VERSION ""

NS_ :

BS_:

BU_: XXX

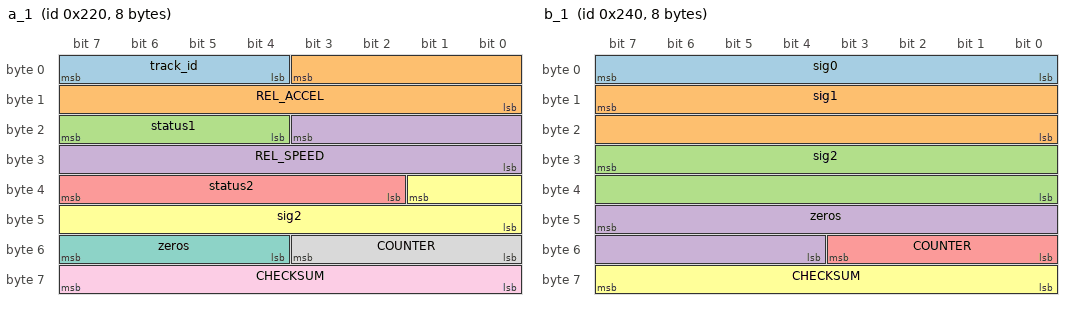
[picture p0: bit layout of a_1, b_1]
BO_ 544 a_1: 8 XXX
 SG_ track_id : 7|4@0+ (1,0) [0|15] "" XXX
 SG_ REL_ACCEL : 3|12@0+ (1,0) [0|31] "" XXX
 SG_ status1 : 23|4@0+ (1,0) [0|15] "" XXX
 SG_ REL_SPEED : 19|12@0+ (1,0) [0|65535] "" XXX
 SG_ status2 : 39|6@0+ (1,0) [0|15] "" XXX
 SG_ sig2 : 33|10@0+ (1,0) [0|255] "" XXX
 SG_ zeros : 55|4@0+ (1,0) [0|15] "" XXX
 SG_ COUNTER : 51|4@0+ (1,0) [0|15] "" XXX
 SG_ CHECKSUM : 63|8@0+ (1,0) [0|255] "" XXX

BO_ 576 b_1: 8 XXX
 SG_ sig0 : 7|8@0+ (1,0) [0|255] "" XXX
 SG_ sig1 : 15|16@0+ (1,0) [0|65535] "" XXX
 SG_ sig2 : 31|16@0+ (1,0) [0|255] "" XXX
 SG_ zeros : 47|12@0+ (1,0) [0|255] "" XXX
 SG_ COUNTER : 51|4@0+ (1,0) [0|15] "" XXX
 SG_ CHECKSUM : 63|8@0+ (1,0) [0|255] "" XXX

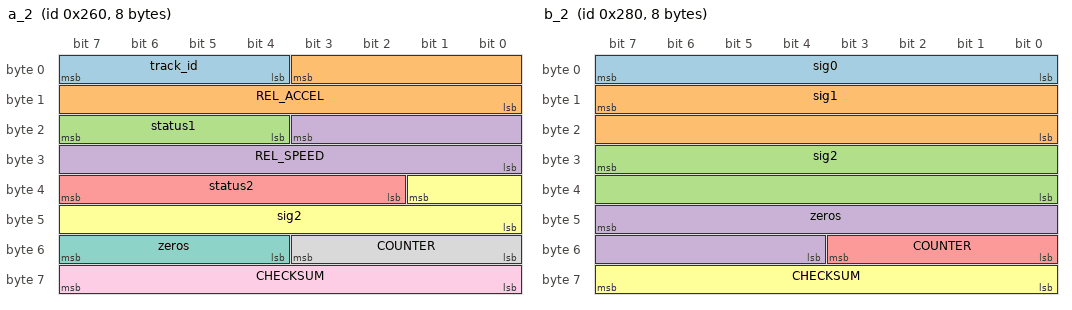
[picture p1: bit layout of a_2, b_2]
BO_ 608 a_2: 8 XXX
 SG_ track_id : 7|4@0+ (1,0) [0|15] "" XXX
 SG_ REL_ACCEL : 3|12@0+ (1,0) [0|31] "" XXX
 SG_ status1 : 23|4@0+ (1,0) [0|15] "" XXX
 SG_ REL_SPEED : 19|12@0+ (1,0) [0|65535] "" XXX
 SG_ status2 : 39|6@0+ (1,0) [0|15] "" XXX
 SG_ sig2 : 33|10@0+ (1,0) [0|255] "" XXX
 SG_ zeros : 55|4@0+ (1,0) [0|15] "" XXX
 SG_ COUNTER : 51|4@0+ (1,0) [0|15] "" XXX
 SG_ CHECKSUM : 63|8@0+ (1,0) [0|255] "" XXX

BO_ 640 b_2: 8 XXX
 SG_ sig0 : 7|8@0+ (1,0) [0|255] "" XXX
 SG_ sig1 : 15|16@0+ (1,0) [0|65535] "" XXX
 SG_ sig2 : 31|16@0+ (1,0) [0|255] "" XXX
 SG_ zeros : 47|12@0+ (1,0) [0|255] "" XXX
 SG_ COUNTER : 51|4@0+ (1,0) [0|15] "" XXX
 SG_ CHECKSUM : 63|8@0+ (1,0) [0|255] "" XXX

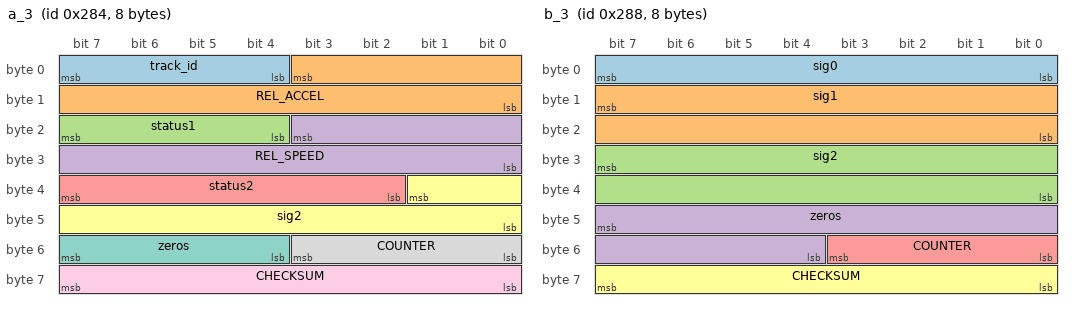
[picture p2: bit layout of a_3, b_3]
BO_ 644 a_3: 8 XXX
 SG_ track_id : 7|4@0+ (1,0) [0|15] "" XXX
 SG_ REL_ACCEL : 3|12@0+ (1,0) [0|31] "" XXX
 SG_ status1 : 23|4@0+ (1,0) [0|15] "" XXX
 SG_ REL_SPEED : 19|12@0+ (1,0) [0|65535] "" XXX
 SG_ status2 : 39|6@0+ (1,0) [0|15] "" XXX
 SG_ sig2 : 33|10@0+ (1,0) [0|255] "" XXX
 SG_ zeros : 55|4@0+ (1,0) [0|15] "" XXX
 SG_ COUNTER : 51|4@0+ (1,0) [0|15] "" XXX
 SG_ CHECKSUM : 63|8@0+ (1,0) [0|255] "" XXX

BO_ 648 b_3: 8 XXX
 SG_ sig0 : 7|8@0+ (1,0) [0|255] "" XXX
 SG_ sig1 : 15|16@0+ (1,0) [0|65535] "" XXX
 SG_ sig2 : 31|16@0+ (1,0) [0|255] "" XXX
 SG_ zeros : 47|12@0+ (1,0) [0|255] "" XXX
 SG_ COUNTER : 51|4@0+ (1,0) [0|15] "" XXX
 SG_ CHECKSUM : 63|8@0+ (1,0) [0|255] "" XXX

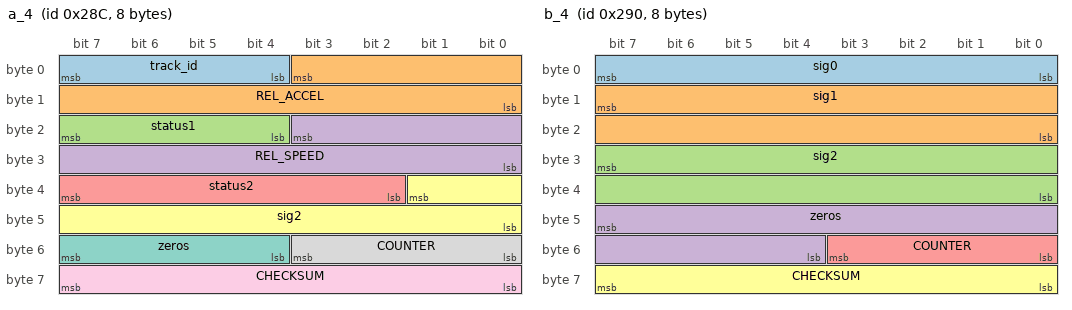
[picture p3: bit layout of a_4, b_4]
BO_ 652 a_4: 8 XXX
 SG_ track_id : 7|4@0+ (1,0) [0|15] "" XXX
 SG_ REL_ACCEL : 3|12@0+ (1,0) [0|31] "" XXX
 SG_ status1 : 23|4@0+ (1,0) [0|15] "" XXX
 SG_ REL_SPEED : 19|12@0+ (1,0) [0|65535] "" XXX
 SG_ status2 : 39|6@0+ (1,0) [0|15] "" XXX
 SG_ sig2 : 33|10@0+ (1,0) [0|255] "" XXX
 SG_ zeros : 55|4@0+ (1,0) [0|15] "" XXX
 SG_ COUNTER : 51|4@0+ (1,0) [0|15] "" XXX
 SG_ CHECKSUM : 63|8@0+ (1,0) [0|255] "" XXX

BO_ 656 b_4: 8 XXX
 SG_ sig0 : 7|8@0+ (1,0) [0|255] "" XXX
 SG_ sig1 : 15|16@0+ (1,0) [0|65535] "" XXX
 SG_ sig2 : 31|16@0+ (1,0) [0|255] "" XXX
 SG_ zeros : 47|12@0+ (1,0) [0|255] "" XXX
 SG_ COUNTER : 51|4@0+ (1,0) [0|15] "" XXX
 SG_ CHECKSUM : 63|8@0+ (1,0) [0|255] "" XXX

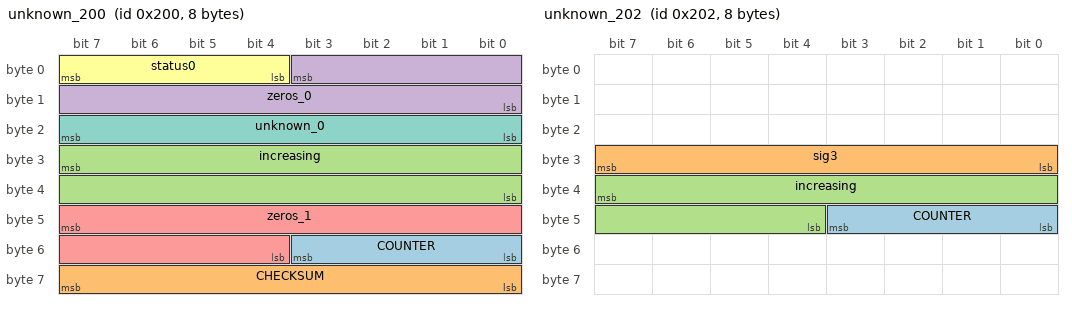
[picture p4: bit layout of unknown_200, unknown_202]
BO_ 512 unknown_200: 8 XXX
 SG_ COUNTER : 51|4@0+ (1,0) [0|15] "" XXX
 SG_ CHECKSUM : 63|8@0+ (1,0) [0|255] "" XXX
 SG_ increasing : 31|16@0+ (1,0) [0|255] "" XXX
 SG_ zeros_0 : 3|12@0+ (1,0) [0|63] "" XXX
 SG_ zeros_1 : 47|12@0+ (1,0) [0|63] "" XXX
 SG_ status0 : 7|4@0+ (1,0) [0|15] "" XXX
 SG_ unknown_0 : 23|8@0+ (1,0) [0|255] "" XXX

BO_ 514 unknown_202: 8 XXX
 SG_ COUNTER : 43|4@0+ (1,0) [0|15] "" XXX
 SG_ sig3 : 31|8@0+ (1,0) [0|65535] "" XXX
 SG_ increasing : 39|12@0+ (1,0) [0|15] "" XXX

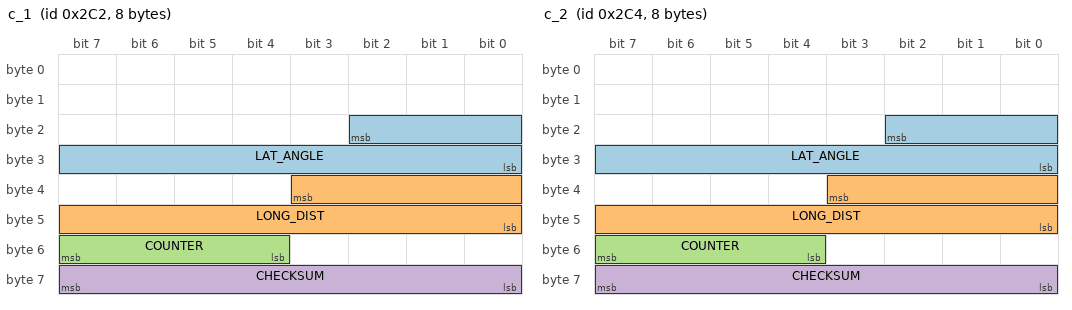
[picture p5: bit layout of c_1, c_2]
BO_ 706 c_1: 8 XXX
 SG_ LAT_ANGLE : 18|11@0+ (0.00048828125,-0.5) [-0.5|0.49951171875] "" XXX
 SG_ LONG_DIST : 35|12@0+ (0.0625,0) [0|255.93752] "m" XXX
 SG_ COUNTER : 55|4@0+ (1,0) [0|15] "" XXX
 SG_ CHECKSUM : 63|8@0+ (1,0) [0|255] "" XXX

BO_ 708 c_2: 8 XXX
 SG_ LAT_ANGLE : 18|11@0+ (0.00048828125,-0.5) [-0.5|0.49951171875] "" XXX
 SG_ LONG_DIST : 35|12@0+ (0.0625,0) [0|255.93752] "m" XXX
 SG_ COUNTER : 55|4@0+ (1,0) [0|15] "" XXX
 SG_ CHECKSUM : 63|8@0+ (1,0) [0|255] "" XXX

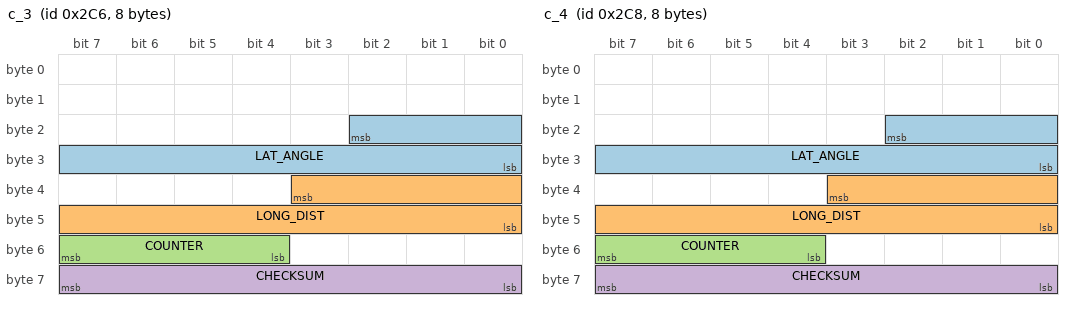
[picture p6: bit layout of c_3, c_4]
BO_ 710 c_3: 8 XXX
 SG_ LAT_ANGLE : 18|11@0+ (0.00048828125,-0.5) [-0.5|0.49951171875] "" XXX
 SG_ LONG_DIST : 35|12@0+ (0.0625,0) [0|255.93752] "m" XXX
 SG_ COUNTER : 55|4@0+ (1,0) [0|15] "" XXX
 SG_ CHECKSUM : 63|8@0+ (1,0) [0|255] "" XXX

BO_ 712 c_4: 8 XXX
 SG_ LAT_ANGLE : 18|11@0+ (0.00048828125,-0.5) [-0.5|0.49951171875] "" XXX
 SG_ LONG_DIST : 35|12@0+ (0.0625,0) [0|255.93752] "m" XXX
 SG_ COUNTER : 55|4@0+ (1,0) [0|15] "" XXX
 SG_ CHECKSUM : 63|8@0+ (1,0) [0|255] "" XXX

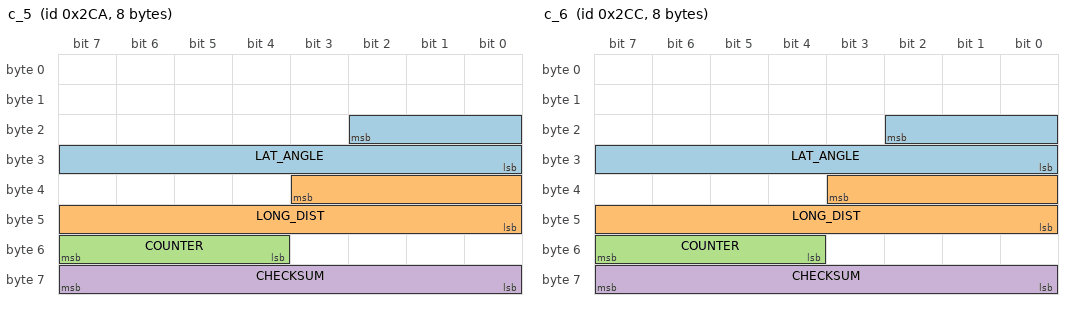
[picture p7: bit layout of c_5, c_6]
BO_ 714 c_5: 8 XXX
 SG_ LAT_ANGLE : 18|11@0+ (0.00048828125,-0.5) [-0.5|0.49951171875] "" XXX
 SG_ LONG_DIST : 35|12@0+ (0.0625,0) [0|255.93752] "m" XXX
 SG_ COUNTER : 55|4@0+ (1,0) [0|15] "" XXX
 SG_ CHECKSUM : 63|8@0+ (1,0) [0|255] "" XXX

BO_ 716 c_6: 8 XXX
 SG_ LAT_ANGLE : 18|11@0+ (0.00048828125,-0.5) [-0.5|0.49951171875] "" XXX
 SG_ LONG_DIST : 35|12@0+ (0.0625,0) [0|255.93752] "m" XXX
 SG_ COUNTER : 55|4@0+ (1,0) [0|15] "" XXX
 SG_ CHECKSUM : 63|8@0+ (1,0) [0|255] "" XXX

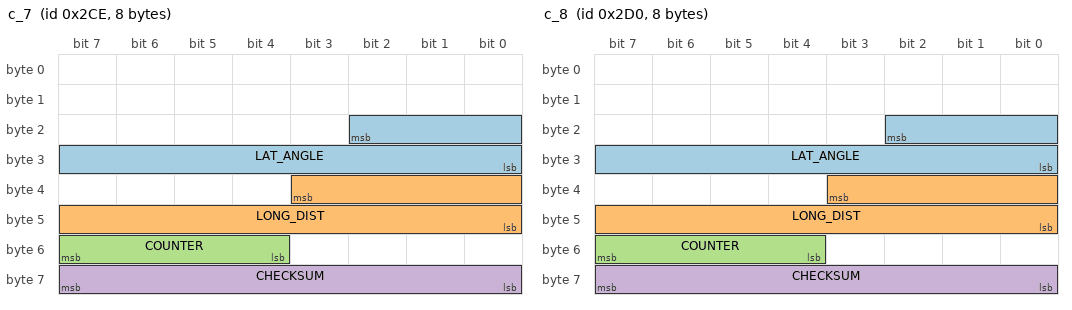
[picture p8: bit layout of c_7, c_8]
BO_ 718 c_7: 8 XXX
 SG_ LAT_ANGLE : 18|11@0+ (0.00048828125,-0.5) [-0.5|0.49951171875] "" XXX
 SG_ LONG_DIST : 35|12@0+ (0.0625,0) [0|255.93752] "m" XXX
 SG_ COUNTER : 55|4@0+ (1,0) [0|15] "" XXX
 SG_ CHECKSUM : 63|8@0+ (1,0) [0|255] "" XXX

BO_ 720 c_8: 8 XXX
 SG_ LAT_ANGLE : 18|11@0+ (0.00048828125,-0.5) [-0.5|0.49951171875] "" XXX
 SG_ LONG_DIST : 35|12@0+ (0.0625,0) [0|255.93752] "m" XXX
 SG_ COUNTER : 55|4@0+ (1,0) [0|15] "" XXX
 SG_ CHECKSUM : 63|8@0+ (1,0) [0|255] "" XXX

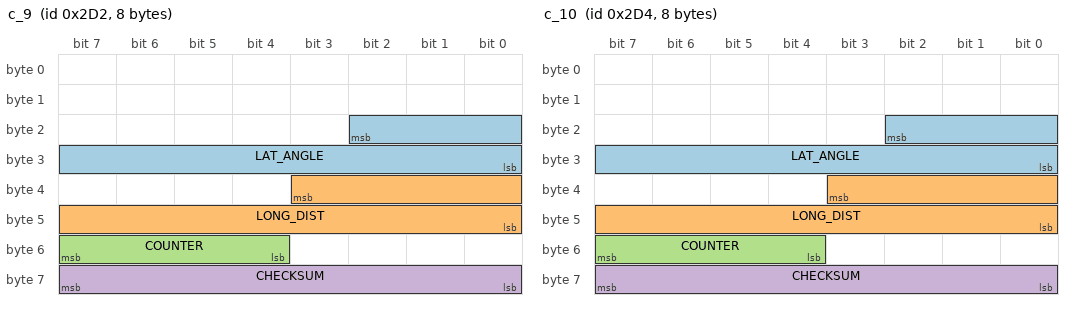
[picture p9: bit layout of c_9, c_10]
BO_ 722 c_9: 8 XXX
 SG_ LAT_ANGLE : 18|11@0+ (0.00048828125,-0.5) [-0.5|0.49951171875] "" XXX
 SG_ LONG_DIST : 35|12@0+ (0.0625,0) [0|255.93752] "m" XXX
 SG_ COUNTER : 55|4@0+ (1,0) [0|15] "" XXX
 SG_ CHECKSUM : 63|8@0+ (1,0) [0|255] "" XXX

BO_ 724 c_10: 8 XXX
 SG_ LAT_ANGLE : 18|11@0+ (0.00048828125,-0.5) [-0.5|0.49951171875] "" XXX
 SG_ LONG_DIST : 35|12@0+ (0.0625,0) [0|255.93752] "m" XXX
 SG_ COUNTER : 55|4@0+ (1,0) [0|15] "" XXX
 SG_ CHECKSUM : 63|8@0+ (1,0) [0|255] "" XXX

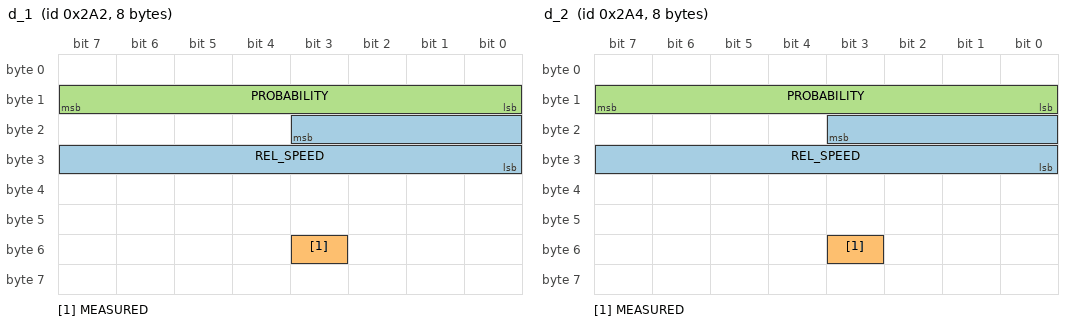
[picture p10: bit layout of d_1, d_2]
BO_ 674 d_1: 8 XXX
 SG_ REL_SPEED : 19|12@0+ (0.25,-128) [-128|127] "m/s" XXX
 SG_ MEASURED : 51|1@0+ (1,0) [0|1] "" XXX
 SG_ PROBABILITY : 15|8@0+ (1,0) [0|255] "" XXX

BO_ 676 d_2: 8 XXX
 SG_ REL_SPEED : 19|12@0+ (0.25,-128) [-128|127] "m/s" XXX
 SG_ MEASURED : 51|1@0+ (1,0) [0|1] "" XXX
 SG_ PROBABILITY : 15|8@0+ (1,0) [0|255] "" XXX

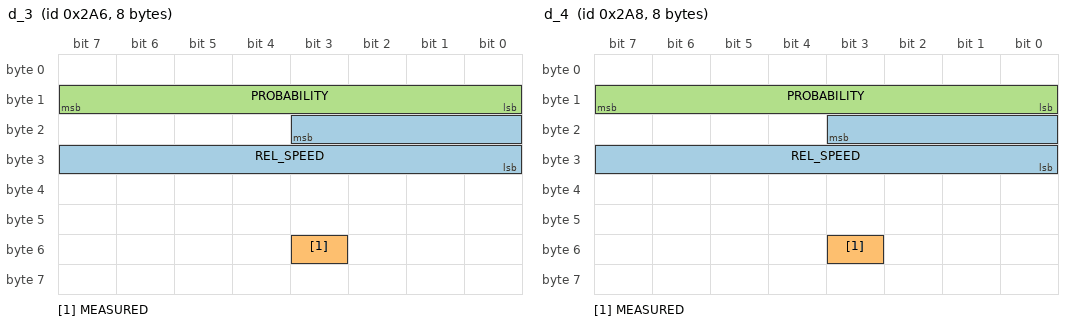
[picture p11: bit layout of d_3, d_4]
BO_ 678 d_3: 8 XXX
 SG_ REL_SPEED : 19|12@0+ (0.25,-128) [-128|127] "m/s" XXX
 SG_ MEASURED : 51|1@0+ (1,0) [0|1] "" XXX
 SG_ PROBABILITY : 15|8@0+ (1,0) [0|255] "" XXX

BO_ 680 d_4: 8 XXX
 SG_ REL_SPEED : 19|12@0+ (0.25,-128) [-128|127] "m/s" XXX
 SG_ MEASURED : 51|1@0+ (1,0) [0|1] "" XXX
 SG_ PROBABILITY : 15|8@0+ (1,0) [0|255] "" XXX

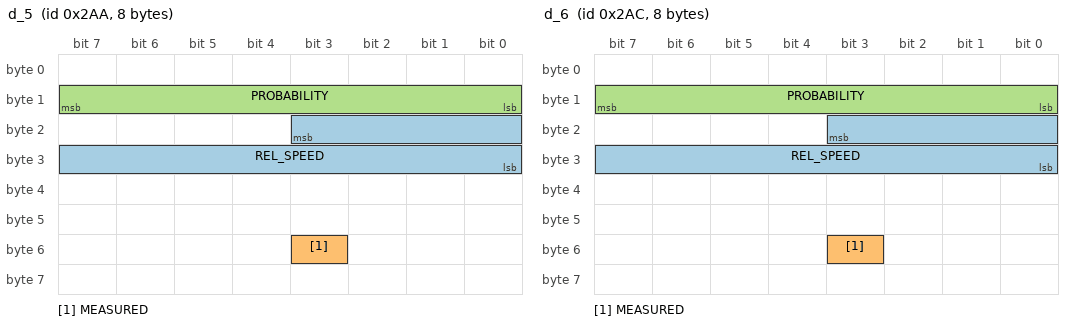
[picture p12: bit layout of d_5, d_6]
BO_ 682 d_5: 8 XXX
 SG_ REL_SPEED : 19|12@0+ (0.25,-128) [-128|127] "m/s" XXX
 SG_ MEASURED : 51|1@0+ (1,0) [0|1] "" XXX
 SG_ PROBABILITY : 15|8@0+ (1,0) [0|255] "" XXX

BO_ 684 d_6: 8 XXX
 SG_ REL_SPEED : 19|12@0+ (0.25,-128) [-128|127] "m/s" XXX
 SG_ MEASURED : 51|1@0+ (1,0) [0|1] "" XXX
 SG_ PROBABILITY : 15|8@0+ (1,0) [0|255] "" XXX

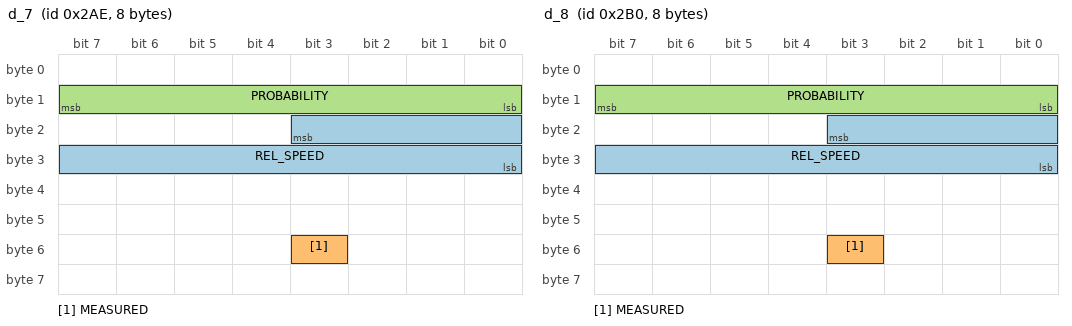
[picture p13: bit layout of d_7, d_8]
BO_ 686 d_7: 8 XXX
 SG_ REL_SPEED : 19|12@0+ (0.25,-128) [-128|127] "m/s" XXX
 SG_ MEASURED : 51|1@0+ (1,0) [0|1] "" XXX
 SG_ PROBABILITY : 15|8@0+ (1,0) [0|255] "" XXX

BO_ 688 d_8: 8 XXX
 SG_ REL_SPEED : 19|12@0+ (0.25,-128) [-128|127] "m/s" XXX
 SG_ MEASURED : 51|1@0+ (1,0) [0|1] "" XXX
 SG_ PROBABILITY : 15|8@0+ (1,0) [0|255] "" XXX

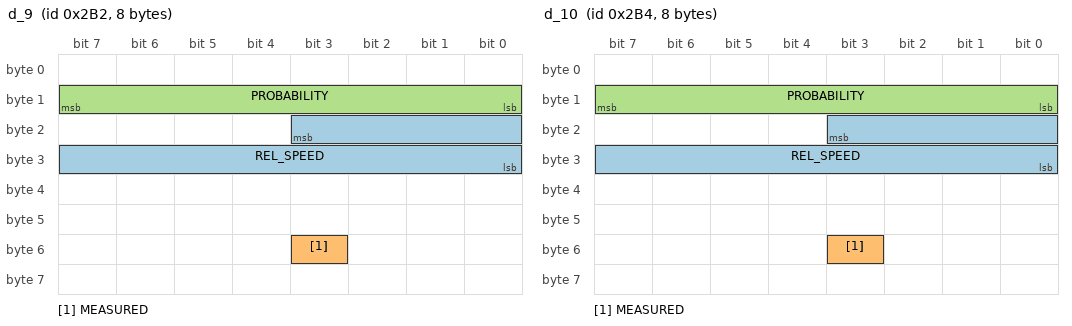
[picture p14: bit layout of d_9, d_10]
BO_ 690 d_9: 8 XXX
 SG_ REL_SPEED : 19|12@0+ (0.25,-128) [-128|127] "m/s" XXX
 SG_ MEASURED : 51|1@0+ (1,0) [0|1] "" XXX
 SG_ PROBABILITY : 15|8@0+ (1,0) [0|255] "" XXX

BO_ 692 d_10: 8 XXX
 SG_ REL_SPEED : 19|12@0+ (0.25,-128) [-128|127] "m/s" XXX
 SG_ MEASURED : 51|1@0+ (1,0) [0|1] "" XXX
 SG_ PROBABILITY : 15|8@0+ (1,0) [0|255] "" XXX

BO_ 672 NEW_MSG_5: 8 XXX
 SG_ NEW_SIGNAL_1 : 9|10@0+ (1,0) [0|1023] "" XXX
 SG_ NEW_SIGNAL_2 : 45|10@0+ (1,0) [0|1023] "" XXX

CM_ SG_ 544 track_id "for message a_1 track_id is always 1, similar for other messages and track_id";
CM_ SG_ 544 REL_ACCEL "perhaps REL_ACCEL because it responds faster and before REL_SPEED";
CM_ SG_ 544 sig2 "perhaps distance to object. LONG_DIST or REL_ACCEL or REL_SPEED";
CM_ SG_ 576 zeros "not always zero, sometimes has value when another car changes lanes";
CM_ SG_ 706 LAT_DIST "positive is to the right, negative is to the left";
